# SF32LB57x register map
File version: 1.0
CPU: CM33 r0p1, little endian, MPU, FPU, 3 interrupt priority bits
Registers are 32-bit, read-write, reset 0x0 unless marked. A register's access mark holds for its fields unless they carry their own. Offsets are from the block's base; [hi:lo] are bit positions.

## I2C1
Base 0x5009C000
Same registers: I2C2 0x5009D000, I2C3 0x5009E000, I2C4 0x5009F000
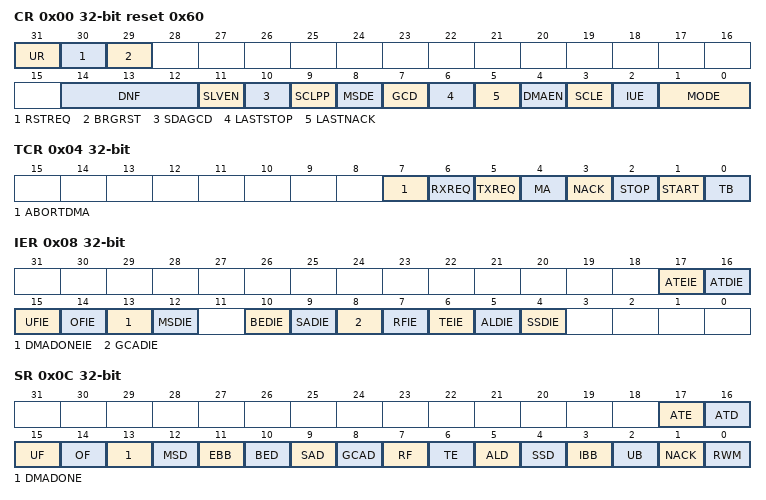
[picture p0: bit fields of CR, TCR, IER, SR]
0x00 CR reset 0x60 — Control register
  [31] UR — Unit Reset. Software need first assert to reset then deassert to release. 0 = No reset. 1 = Reset I2C module.
  [30] RSTREQ — I2C will do bus reset upon this bit set. Will be cleared by HW automatically after RSTCYC cycles of SCL generated. 1 = request for i2c bus reset 0 = bus reset finished
  [29] BRGRST — Reset bus related state machine and signals. Will be cleared by HW automatically 1 = request for reset 0 = reset finished
  [14:12] DNF — Digital noise filter These bits are used to configure the digital noise filter on SDA and SCL input. The digital filter will filter spikes with a length of up to DNF[3:0]*Tpclk. 0: Digital filter disabled 1: Digital filter enabled and filtering capability up to 1 Tpclk ... 7: digital filter enabled and filtering capability up to 7 Tpclk Note: Digital filter is added to analog filter. Digital filter will introduce delay on SCL and SDA processing, which is essential in hs-mode.
  [11] SLVEN — Slave mode Enable for SCL. 0 = Disable slave mode. Will not monitor slave address on I2C bus. 1 = Enable slave mode. Will monitor slave address on I2C bus.
  [10] SDAGCD — Glitch cancellation Disable for SDA. 0 = Enable glitch cancellation for SDA 1 = Disable glitch cancellation for SDA
  [9] SCLPP — Push-pull mode Enable for SCL. 0 = open drain output for SCL. 1 = Push-pull output for SCL
  [8] MSDE — Master Stop Detected Enable: 0 = Master Stop Detect (MSD) status is not enabled. 1 = Master Stop Detect (MSD) status is enabled.
  [7] GCD — General Call Disable: 0 = Enable the I2C to respond to general call messages. 1 = Disable I2C response to general call messages as a slave. This bit must be set when sending a master mode general call message from the I2C.
  [6] LASTSTOP — Generate STOP for last DMA transfer
  [5] LASTNACK — Generate NACK for last DMA Read transfer
  [4] DMAEN — DMA Enable for both TX and RX 0 = DMA mode is NOT enabled 1 = DMA mode enabled
  [3] SCLE — SCL Enable: 0 = Disables the I2C from driving the SCL line. 1 = Enables the I2C clock output for master-mode operation.
  [2] IUE — I2C Unit Enable: 0 = Disables the unit and does not master any transactions or respond to any slave transactions. 1 = Enables the I2C (defaults to slave-receive mode). Software must guarantee the I2C bus is idle before setting this bit.
  [1:0] MODE — Bus Mode (Master operation): 2'b00: standard-mode 2'b01: fast-mode and fast-mode plus 2'b10: HS-mode (standard mode when not doing a high speed transfer) 2'b11: HS-mode (fast mode when not doing a high speed transfer) Bus Mode (Slave operation): 2'b0x: HS-mode is disabled. I2C unit uses Standard/Fast mode timing on the SDA pin. 2'b1x: HS-mode is enabled. I2C unit uses HS-mode timing on the SDA pin when a master code is received.
0x04 TCR — Transfer Control register
  [7] ABORTDMA — Abort DMA operation. Will be cleared by HW automatically
  [6] RXREQ — Request DMA RX. Will be cleared by HW automatically
  [5] TXREQ — Request DMA TX. Will be cleared by HW automatically
  [4] MA — Master Abort: Used by the I2C in master mode to generate a Stop without transmitting another data byte: 0 = The I2C transmits Stop on if TCR[STOP] is set. 1 = The I2C sends Stop without data transmission. When in master-transmit mode, after transmitting a data byte, the TCR[TB] bit is cleared. When no more data bytes need to be sent, setting master abort bit sends the Stop. The TCR[TB] bit must remain clear. In master-receive mode, when a NAK is sent without a Stop (TCR[STOP] bit was not set) and CPU does not send a repeated Start, setting this bit sends the Stop. Once again, the TCR[TB] bit must remain clear. Master Abort can be done immediately after the address phase (Master Transmit mode only).
  [3] NACK — The positive/negative acknowledge control bit, defines the type of acknowledge pulse sent by the I2C when in master receive mode: 0 = Send a positive acknowledge (ACK) pulse after receiving a data byte. 1 = Send a negative acknowledge (NACK) pulse after receiving a data byte. The I2C automatically sends an ACK pulse when responding to its slave address or when responding in slave-receive mode, regardless of the NACK control-bit setting.
  [2] STOP — Stop: Used to initiate a Stop condition after transferring the next data byte on the I2C bus when in master mode. In master-receive mode, the NACK control bit must be set in conjunction with the STOP bit. 0 = Do not send a Stop. 1 = Send a Stop.
  [1] START — Start: Used to initiate a Start condition to the I2C unit when in master mode. 0 = Do not send a Start pulse. 1 = Send a Start pulse.
  [0] TB — Transfer Byte: Used to send or receive a byte on the I2C bus: 0 = Cleared by I2C when the byte is sent/received. 1 = Send/receive a byte. CPU can monitor this bit to determine when the byte transfer has completed. In master or slave mode, after each byte transfer including acknowledge pulse, the I2C holds the SCL line low (inserting wait states) until TB is set.
0x08 IER — Interrupt Enable register
  [17] ATEIE — Autonomous Task Error Interrupt Enable 0 = Autonomous Task Error interrupt is not enabled 1 = Autonomous Task Error interrupt is enabled
  [16] ATDIE — Autonomous Task Done Interrupt Enable 0 = Autonomous Task Done interrupt is not enabled 1 = Autonomous Task Done interrupt is enabled
  [15] UFIE — FIFO Underflow Interrupt Enable 0 = FIFO Underflow interrupt is not enabled 1 = FIFO Underflow interrupt is enabled
  [14] OFIE — FIFO Overflow Interrupt Enable 0 = FIFO Overflow interrupt is not enabled 1 = FIFO Overflow interrupt is enabled
  [13] DMADONEIE — DMA Transaction Done Interrupt Enable 0 = DMA Transaction done interrupt is not enabled. 1 = DMA Transaction done interrupt is enabled.
  [12] MSDIE — Master Stop Detected Interrupt Enable: 0 = Disable interrupt. 1 = Enables the I2C unit to interrupt upon detecting a Master Stop sent by the I2C unit.
  [10] BEDIE — Bus Error Detected Interrupt Enable: 0 = Disable interrupt. 1 = Enables the I2C to interrupt for the following I2C bus errors: As a master transmitter, no ACK was detected after a byte was sent. As a slave receiver, the I2C generated a NACK pulse. Software is responsible for guaranteeing that misplaced Start and Stop conditions do not occur.
  [9] SADIE — Slave Address Detected Interrupt Enable: 0 = Disable interrupt. 1 = Enables the I2C to interrupt upon detecting a slave address match or a general call address.
  [8] GCADIE — General Call Address Detected Interrupt Enable: 0 = Disable interrupt. 1 = Enables the I2C to interrupt when General Call Address Detected.
  [7] RFIE — DBR Receive Full Interrupt Enable: 0 = Disable interrupt. 1 = Enables the I2C to interrupt when the DBR has received a data byte from the I2C bus.
  [6] TEIE — DBR Transmit Empty Interrupt Enable: 0 = Disable interrupt. 1 = Enables the I2C to interrupt after transmitting a byte onto the I2C bus.
  [5] ALDIE — Arbitration Loss Detected Interrupt Enable: 0 = Disable interrupt. 1 = Enables the I2C to interrupt upon losing arbitration while in master mode.
  [4] SSDIE — Slave Stop Detected Interrupt Enable: 0 = Disable interrupt. 1 = Enables the I2C to interrupt when it detects a Stop condition while in slave mode.
0x0C SR — Status register
  [17] ATE — Autonomous Task Error. Asserted when Autonomous Task error occurs. Cleared if write 1
  [16] ATD — Autonomous Task Done. Asserted when Autonomous Task done. Cleared if write 1 or another autonomous task triggered
  [15] UF — FIFO Underflow Flag. Asserted when FIFO is empty and a POP request generated without a PUSH. Cleared if write 1
  [14] OF — FIFO Overflow Flag. Asserted when FIFO is full and a PUSH request generated without a POP. Cleared if write 1
  [13] DMADONE — DMA Transaction Done. Asserted when both APB and I2C bus have finished transfer. Cleared if write 1
  [12] MSD — Master Stop Detected: 0 = No Master Stop Detected. 1 = This bit is set by the I2C unit when all of the following are true: This bit is enabled (CR[MSDE] = 1); I2C unit is configured as a master; I2C transmits a STOP signal
  [11] EBB — Early Bus Busy 0 = I2C bus is idle or the I2C is using the bus (that is, unit busy). 1 = Set when the unit detects that the SCL or SDA line is low without a START condition. Bit will remain set until the I2C unit detects the bus is idle by detecting a STOP condition. Bit will also be set whenever the IBB bit is set.
  [10] BED — Bus Error Detected: 0 = No error detected. 1 = The I2C sets this bit when it detects one of the following error conditions: As a master transmitter, no ACK was detected on the interface after a byte was sent. As a slave receiver, the I2C generates a NACK pulse. When an error occurs, I2C bus transactions continue. Software must guarantee that misplaced Start and Stop conditions do not occur.
  [9] SAD — Slave Address Detected: 0 = No slave address was detected. 1 = The I2C detected a seven-bit address that matches the general call address or SAR. An interrupt is signalled when enabled in the CR.
  [8] GCAD — General Call Address Detected: 0 = No general call address received. 1 = I2C received a general call address.
  [7] RF — DBR Receive Full: 0 = The DBR has not received a new data byte or the I2C is idle. 1 = The DBR register received a new data byte from the I2C bus. An interrupt is signalled when enabled in the CR.
  [6] TE — DBR Transmit Empty: 0 = The data byte is still being transmitted. 1 = The I2C has finished transmitting a data byte on the I2C bus. An interrupt is signalled when enabled in the CR.
  [5] ALD — Arbitration Loss Detected: Used during multi-master operation: 0 = Cleared when arbitration is won or never took place. 1 = Set when the I2C loses arbitration.
  [4] SSD — Slave Stop Detected: 0 = No Stop detected. 1 = Set when the I2C detects a Stop while in slave-receive or slave-transmit mode.
  [3] IBB — I2C Bus Busy: 0 = I2C bus is idle or the I2C is using the bus (that is, unit busy). 1 = Set when the I2C bus is busy but local I2C is not involved in the transaction.
  [2] UB — Unit Busy: 0 = I2C not busy. 1 = Set when local I2C is busy. This is defined as the time between the first Start and Stop.
  [1] NACK — ACK/NACK Status: 0 = The I2C received or sent an ACK on the bus. 1 = The I2C received or sent a NACK.on the bus. This bit is used in slave-transmit mode to determine when the byte transferred is the last one. This bit is updated after each byte and ACK/NACK information is received.
  [0] RWM — Read/write Mode: 0 = The I2C is in master-transmit or slave-receive mode. 1 = The I2C is in master-receive or slave-transmit mode. This is the R/nW bit of the slave address. It is cleared automatically by hardware after a Stop state.
0x10 DBR — Data Buffer register
  [7:0] DATA — use the I2C Data Buffer register to transmit and receive data from the I2C bus. The DBR is accessed by software on one Side and by the I2C Shift register on the other. The DBR receives data coming into the I2C unit after a full byte is received and acknowledged. CPU writes data going out of the I2C to the DBR and sends it to the serial bus. When the I2C is in transmit mode (master or slave), CPU writes data to the DBR over the internal bus. CPU write data to the DBR when a master transaction is initiated or when the DBR transmit-empty interrupt is signalled. Data moves from the DBR to the Shift register when the transfer byte bit is set. The DBR transmit-empty interrupt is signalled (if enabled) when a byte is transferred on the I2C bus and the acknowledge cycle is complete. If the DBR is not written, and a Stop condition is not in place before the I2C bus is ready to transfer the next byte packet, the I2C unit inserts wait states until CPU writes the DBR and sets the transfer byte bit. When the I2C is in receive mode (master or slave), CPU reads DBR data over the internal bus. CPU reads data from the DBR when the DBR receive-full interrupt is signalled. The data moves from the Shift register to the DBR when the acknowledge cycle is complete. The I2C inserts wait states until the DBR is read. After the software reads the DBR, CR[NACK] are written by the software, allowing the next byte transfer to proceed to the I2C bus. In DMA mode, DBR is automatically filled from FIFO in master transmit mode, or fetched and stored in FIFO in master receive mode until DMA done or aborted.
0x14 SAR reset 0x47 — Slave Address Register
  [6:0] ADDR — The seven-bit address to which the I2C responds when in slave-receive mode
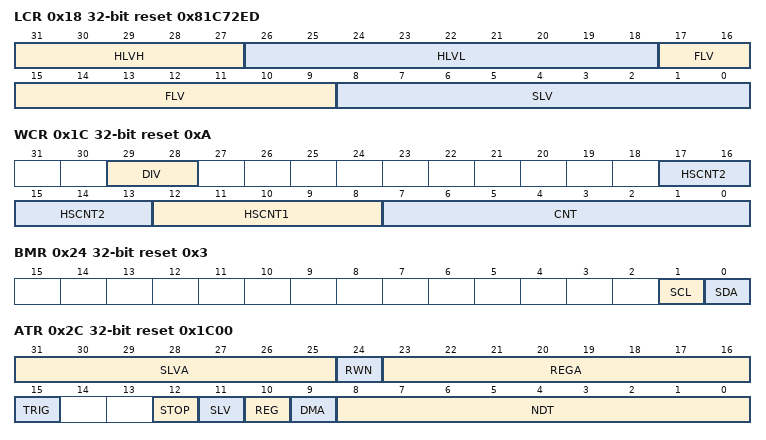
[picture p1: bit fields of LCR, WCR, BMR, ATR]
0x18 LCR reset 0x81C72ED — Load Count Register
  [31:27] HLVH — Decrementer Load value for High Speed Mode SCL (master mode) for high phase. Thigh=Tfclk*(HLVH+4+DNF)
  [26:18] HLVL — Decrementer Load value for High Speed Mode SCL (master mode) for low phase. Tlow=Tfclk*(HLVL+3+DNF). Data rate is generated as 1/(Thigh+Tlow), or fpclk/(HLVH+HLVL+7+2*DNF). 3.2Mbps data rate is generated by default if fclk is 48MHz. HLVL also controls setup time and hold time for START and STOP condition in High Speed Mode(master mode). Thdsta=Tsusta=Tsusto=Tfclk*(HLVL+1)
  [17:9] FLV — Decrementer Load value for Fast Mode (or Fast Mode Plus) SCL (master mode) for both high and low phase. Data rate is generated as Ffclk/(FLV+max(FLV,CNT*2+6)+7+DNF) approximately. 400kbps data rate is generated by default if fclk is 48MHz. FLV also controls setup time and hold time for START and STOP condition in Fast Mode(master mode). Thdsta=Tsusta=Tsusto=Tfclk*FLV
  [8:0] SLV — Decrementer Load value for Standard Mode SCL (master mode) for both high and low phase. Data rate is generated as Ffclk/(SLV+max(SLV,CNT*2+6)+7+DNF) approximately. 100kbps data rate is generated by default if fclk is 48MHz. SLV also controls setup time and hold time for START and STOP condition in Standard Mode(master mode). Thdsta=Tsusta=Tsusto=Tfclk*SLV
0x1C WCR reset 0xA — Wait Count Register
  [29:28] DIV — reserved
  [17:13] HSCNT2
  [12:8] HSCNT1 — Count value for defining high speed mode hold time. Thddat=Tfclk*max(3+DNF,HSCNT1)
  [7:0] CNT — Controls the counter values defining the setup and hold times in standard and fast mode Tvddat=Thddat=Tfclk*(CNT+2) Tsudat=max(Tlow-Thddat,Thddat) Lower counter values may violate setup and hold times.
0x20 RCCR reset 0x9 — Bus Reset Cycle Counter Register
  [3:0] RSTCYC — The cycles of SCL during bus reset
0x24 BMR reset 0x3 — Bus Monitor Register
  [1] SCL — continuously reflects the value of the SCL pin. The values of these pins are recorded, so software can determine when the I2C bus is hung and the I2C unit must be reset.
  [0] SDA — continuously reflects the value of the SDA pin.
0x28 DNR — DMA number register
  [8:0] NDT — Write as number of data to transfer in byte. Read as left data number to transfer
0x2C ATR reset 0x1C00 — Autonomous Task register
  [31:25] SLVA — 7-bit I2C address of slave device for autonomous task
  [24] RWN — read or write task 0 = write mode. Write data to slave device 1 = read mode. Read data from slave device
  [23:16] REGA — register address of slave device for autonomous task
  [15] TRIG — Trigger autonomous task. Will be cleared by HW automatically
  [12] STOP — 0: tast end without STOP bit in non-DMA mode. In DMA mode, STOP bit depends on CR_LASTSTOP. 1: tast end with STOP bit in non-DMA mode. In DMA mode, STOP bit depends on CR_LASTSTOP.
  [11] SLV — 0: the first slave address(write) will not be transmitted, however the second slave address(read) will be transmitted when read 1: the first slave address(write) will be transmitted when read and write, and the second slave address(read) will be transmitted when read
  [10] REG — 0: register address of slave device will not be transmitted 1: register address of slave device will be transmitted
  [9] DMA — 0 = DMA not enabled during autonomous task. Only single byte data will be transferred. Data to be written should reside in ATR_NDT[7:0], and read data will be stored in DBR_DATA when task completed. 1 = data will be transfered by DMA during autonomous task. Up to 511-byte data will be transferred according to ATR_NDT.
  [8:0] NDT — If ATR_DMA asserted, ATR_NDT is the byte number of data to be transferred by DMA during autonomous task. Left data number during transmission could be read from DNR_NDT. If ATR_DMA deasserted, ATR_NDT[7:0] is the data to be written in write mode.
0x30 FIFO
  [7:0] DATA — Write to push send data into FIFO. Read to pop received data from FIFO
0x34 DBG — Debug Register
  [31:0] DATA — Debug data
